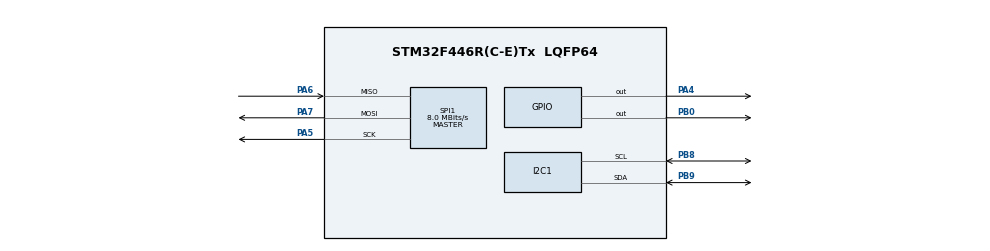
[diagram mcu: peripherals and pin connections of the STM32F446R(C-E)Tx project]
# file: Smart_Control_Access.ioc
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FREERTOS.Mutexes01=lcdMutex,Dynamic,NULL,Available
FREERTOS.Queues01=rfidQueue,4,uint16_t,0,Dynamic,NULL,NULL;authQueue,1,uint16_t,0,Dynamic,NULL,NULL
FREERTOS.Tasks01=defaultTask,24,128,StartDefaultTask,Default,NULL,Dynamic,NULL,NULL;RFID_Task,24,256,StartTask02,Default,NULL,Dynamic,NULL,NULL;AUTH_Task,32,256,StartTask03,Default,NULL,Dynamic,NULL,NULL;DOOR_Task,16,256,StartTask04,Default,NULL,Dynamic,NULL,NULL;LCD_Tsk,8,256,StartTask05,Default,NULL,Dynamic,NULL,NULL
Mcu.Family=STM32F4
Mcu.Name=STM32F446R(C-E)Tx
Mcu.Package=LQFP64
NVIC.PriorityGroup=NVIC_PRIORITYGROUP_4
PA4.PinState=GPIO_PIN_SET
PA4.Signal=GPIO_Output
PA5.Mode=Full_Duplex_Master
PA5.Signal=SPI1_SCK
PA6.Mode=Full_Duplex_Master
PA6.Signal=SPI1_MISO
PA7.Mode=Full_Duplex_Master
PA7.Signal=SPI1_MOSI
PB0.Signal=GPIO_Output
PB8.Mode=I2C
PB8.Signal=I2C1_SCL
PB9.Mode=I2C
PB9.Signal=I2C1_SDA
ProjectManager.HeapSize=0x200
ProjectManager.StackSize=0x400
ProjectManager.TargetToolchain=STM32CubeIDE
RCC.CortexFreq_Value=16000000
RCC.USBFreq_Value=96000000
RCC.VCOOutputFreq_Value=192000000
SPI1.CalculateBaudRate=8.0 MBits/s
SPI1.Direction=SPI_DIRECTION_2LINES
SPI1.Mode=SPI_MODE_MASTER
SPI1.VirtualType=VM_MASTER
VP_FREERTOS_VS_CMSIS_V2.Mode=CMSIS_V2
board=custom

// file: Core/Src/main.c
/* USER CODE BEGIN Header */
/**
  ******************************************************************************
  * @file           : main.c
  * @brief          : Main program body
  ******************************************************************************
  * @attention
  *
  * Copyright (c) 2026 STMicroelectronics.
  * All rights reserved.
  *
  * This software is licensed under terms that can be found in the LICENSE file
  * in the root directory of this software component.
  * If no LICENSE file comes with this software, it is provided AS-IS.
  *
  ******************************************************************************
  */
/* USER CODE END Header */
#include "main.h"
#include "cmsis_os.h"
#include <stdint.h>
#include "rtos_tasks.h"
#include "lcd.h"
#include "auth.h"
#include "door_control.h"
#include "mfrc522.h"

I2C_HandleTypeDef hi2c1;

SPI_HandleTypeDef hspi1;

/* Definitions for defaultTask */
osThreadId_t defaultTaskHandle;
const osThreadAttr_t defaultTask_attributes = {
  .name = "defaultTask",
  .stack_size = 128 * 4,
  .priority = (osPriority_t) osPriorityNormal,
};
/* Definitions for RFID_Task */
osThreadId_t RFID_TaskHandle;
const osThreadAttr_t RFID_Task_attributes = {
  .name = "RFID_Task",
  .stack_size = 256 * 4,
  .priority = (osPriority_t) osPriorityNormal,
};
/* Definitions for AUTH_Task */
osThreadId_t AUTH_TaskHandle;
const osThreadAttr_t AUTH_Task_attributes = {
  .name = "AUTH_Task",
  .stack_size = 256 * 4,
  .priority = (osPriority_t) osPriorityAboveNormal,
};
/* Definitions for DOOR_Task */
osThreadId_t DOOR_TaskHandle;
const osThreadAttr_t DOOR_Task_attributes = {
  .name = "DOOR_Task",
  .stack_size = 256 * 4,
  .priority = (osPriority_t) osPriorityBelowNormal,
};
/* Definitions for LCD_Tsk */
osThreadId_t LCD_TskHandle;
const osThreadAttr_t LCD_Tsk_attributes = {
  .name = "LCD_Tsk",
  .stack_size = 256 * 4,
  .priority = (osPriority_t) osPriorityLow,
};
/* Definitions for rfidQueue */
osMessageQueueId_t rfidQueueHandle;
const osMessageQueueAttr_t rfidQueue_attributes = {
  .name = "rfidQueue"
};
/* Definitions for authQueue */
osMessageQueueId_t authQueueHandle;
const osMessageQueueAttr_t authQueue_attributes = {
  .name = "authQueue"
};
/* Definitions for lcdMutex */
osMutexId_t lcdMutexHandle;
const osMutexAttr_t lcdMutex_attributes = {
  .name = "lcdMutex"
};

void SystemClock_Config(void);
static void MX_GPIO_Init(void);
static void MX_I2C1_Init(void);
static void MX_SPI1_Init(void);
void StartDefaultTask(void *argument);
void StartTask02(void *argument);
void StartTask03(void *argument);
void StartTask04(void *argument);
void StartTask05(void *argument);

int main(void)
{

  /* MCU Configuration--------------------------------------------------------*/

  /* Reset of all peripherals, Initializes the Flash interface and the Systick. */
  HAL_Init();

  /* Configure the system clock */
  SystemClock_Config();

  /* Initialize all configured peripherals */
  MX_GPIO_Init();
  MX_I2C1_Init();
  MX_SPI1_Init();
  /* USER CODE BEGIN 2 */
  // CREATE QUEUES
  osMessageQueueId_t rfidQueue = osMessageQueueNew(4, sizeof(uint8_t)*4, NULL);
  osMessageQueueId_t authQueue = osMessageQueueNew(4, sizeof(uint8_t), NULL);

  // CREATE MUTEX
  osMutexId_t lcdMutex = osMutexNew(NULL);

  // CREATE TASKS
  osThreadNew(RFID_Task, NULL, NULL);
  osThreadNew(AUTH_Task, NULL, NULL);
  osThreadNew(DOOR_Task, NULL, NULL);
  osThreadNew(LCD_Task, NULL, NULL);

  /* USER CODE END 2 */

  /* Init scheduler */
  osKernelInitialize();
  /* Create the mutex(es) */
  /* creation of lcdMutex */
  lcdMutexHandle = osMutexNew(&lcdMutex_attributes);

  /* Create the queue(s) */
  /* creation of rfidQueue */
  rfidQueueHandle = osMessageQueueNew (4, sizeof(uint16_t), &rfidQueue_attributes);

  /* creation of authQueue */
  authQueueHandle = osMessageQueueNew (1, sizeof(uint16_t), &authQueue_attributes);

  /* Create the thread(s) */
  /* creation of defaultTask */
  defaultTaskHandle = osThreadNew(StartDefaultTask, NULL, &defaultTask_attributes);

  /* creation of RFID_Task */
  RFID_TaskHandle = osThreadNew(StartTask02, NULL, &RFID_Task_attributes);

  /* creation of AUTH_Task */
  AUTH_TaskHandle = osThreadNew(StartTask03, NULL, &AUTH_Task_attributes);

  /* creation of DOOR_Task */
  DOOR_TaskHandle = osThreadNew(StartTask04, NULL, &DOOR_Task_attributes);

  /* creation of LCD_Tsk */
  LCD_TskHandle = osThreadNew(StartTask05, NULL, &LCD_Tsk_attributes);

  /* Start scheduler */
  osKernelStart();

  /* We should never get here as control is now taken by the scheduler */

  /* Infinite loop */
  while (1)
  {

  }
}

void SystemClock_Config(void)
{
  RCC_OscInitTypeDef RCC_OscInitStruct = {0};
  RCC_ClkInitTypeDef RCC_ClkInitStruct = {0};

  /** Configure the main internal regulator output voltage
  */
  __HAL_RCC_PWR_CLK_ENABLE();
  __HAL_PWR_VOLTAGESCALING_CONFIG(PWR_REGULATOR_VOLTAGE_SCALE3);

  /** Initializes the RCC Oscillators according to the specified parameters
  * in the RCC_OscInitTypeDef structure.
  */
  RCC_OscInitStruct.OscillatorType = RCC_OSCILLATORTYPE_HSI;
  RCC_OscInitStruct.HSIState = RCC_HSI_ON;
  RCC_OscInitStruct.HSICalibrationValue = RCC_HSICALIBRATION_DEFAULT;
  RCC_OscInitStruct.PLL.PLLState = RCC_PLL_NONE;
  if (HAL_RCC_OscConfig(&RCC_OscInitStruct) != HAL_OK)
  {
    Error_Handler();
  }

  /** Initializes the CPU, AHB and APB buses clocks
  */
  RCC_ClkInitStruct.ClockType = RCC_CLOCKTYPE_HCLK|RCC_CLOCKTYPE_SYSCLK
                              |RCC_CLOCKTYPE_PCLK1|RCC_CLOCKTYPE_PCLK2;
  RCC_ClkInitStruct.SYSCLKSource = RCC_SYSCLKSOURCE_HSI;
  RCC_ClkInitStruct.AHBCLKDivider = RCC_SYSCLK_DIV1;
  RCC_ClkInitStruct.APB1CLKDivider = RCC_HCLK_DIV1;
  RCC_ClkInitStruct.APB2CLKDivider = RCC_HCLK_DIV1;

  if (HAL_RCC_ClockConfig(&RCC_ClkInitStruct, FLASH_LATENCY_0) != HAL_OK)
  {
    Error_Handler();
  }
}

static void MX_I2C1_Init(void)
{

  hi2c1.Instance = I2C1;
  hi2c1.Init.ClockSpeed = 100000;
  hi2c1.Init.DutyCycle = I2C_DUTYCYCLE_2;
  hi2c1.Init.OwnAddress1 = 0;
  hi2c1.Init.AddressingMode = I2C_ADDRESSINGMODE_7BIT;
  hi2c1.Init.DualAddressMode = I2C_DUALADDRESS_DISABLE;
  hi2c1.Init.OwnAddress2 = 0;
  hi2c1.Init.GeneralCallMode = I2C_GENERALCALL_DISABLE;
  hi2c1.Init.NoStretchMode = I2C_NOSTRETCH_DISABLE;
  if (HAL_I2C_Init(&hi2c1) != HAL_OK)
  {
    Error_Handler();
  }

}

static void MX_SPI1_Init(void)
{

  /* SPI1 parameter configuration*/
  hspi1.Instance = SPI1;
  hspi1.Init.Mode = SPI_MODE_MASTER;
  hspi1.Init.Direction = SPI_DIRECTION_2LINES;
  hspi1.Init.DataSize = SPI_DATASIZE_8BIT;
  hspi1.Init.CLKPolarity = SPI_POLARITY_LOW;
  hspi1.Init.CLKPhase = SPI_PHASE_1EDGE;
  hspi1.Init.NSS = SPI_NSS_SOFT;
  hspi1.Init.BaudRatePrescaler = SPI_BAUDRATEPRESCALER_2;
  hspi1.Init.FirstBit = SPI_FIRSTBIT_MSB;
  hspi1.Init.TIMode = SPI_TIMODE_DISABLE;
  hspi1.Init.CRCCalculation = SPI_CRCCALCULATION_DISABLE;
  hspi1.Init.CRCPolynomial = 10;
  if (HAL_SPI_Init(&hspi1) != HAL_OK)
  {
    Error_Handler();
  }

}

static void MX_GPIO_Init(void)
{
  GPIO_InitTypeDef GPIO_InitStruct = {0};

  /* GPIO Ports Clock Enable */
  __HAL_RCC_GPIOA_CLK_ENABLE();
  __HAL_RCC_GPIOB_CLK_ENABLE();

  /*Configure GPIO pin Output Level */
  HAL_GPIO_WritePin(GPIOA, GPIO_PIN_4, GPIO_PIN_SET);

  /*Configure GPIO pin Output Level */
  HAL_GPIO_WritePin(GPIOB, GPIO_PIN_0, GPIO_PIN_RESET);

  /*Configure GPIO pin : PA4 */
  GPIO_InitStruct.Pin = GPIO_PIN_4;
  GPIO_InitStruct.Mode = GPIO_MODE_OUTPUT_PP;
  GPIO_InitStruct.Pull = GPIO_NOPULL;
  GPIO_InitStruct.Speed = GPIO_SPEED_FREQ_LOW;
  HAL_GPIO_Init(GPIOA, &GPIO_InitStruct);

  /*Configure GPIO pin : PB0 */
  GPIO_InitStruct.Pin = GPIO_PIN_0;
  GPIO_InitStruct.Mode = GPIO_MODE_OUTPUT_PP;
  GPIO_InitStruct.Pull = GPIO_NOPULL;
  GPIO_InitStruct.Speed = GPIO_SPEED_FREQ_LOW;
  HAL_GPIO_Init(GPIOB, &GPIO_InitStruct);

}

void StartDefaultTask(void *argument)
{
  for(;;)
  {
    osDelay(1);
  }
}

void StartTask02(void *argument)
{
  for(;;)
  {
    osDelay(1);
  }
}

void StartTask03(void *argument)
{
  for(;;)
  {
    osDelay(1);
  }
}

void StartTask04(void *argument)
{
  for(;;)
  {
    osDelay(1);
  }
}

void StartTask05(void *argument)
{
  for(;;)
  {
    osDelay(1);
  }
}

void Error_Handler(void)
{
  __disable_irq();
  while (1)
  {
  }
}
